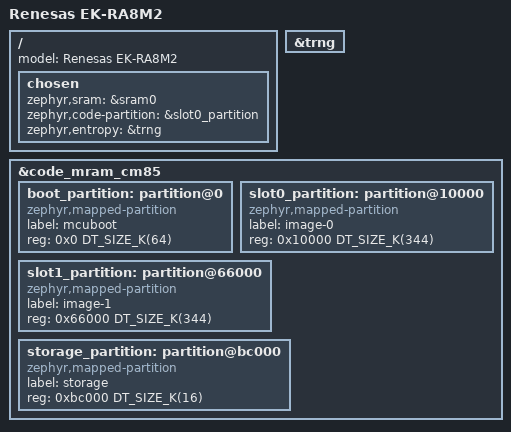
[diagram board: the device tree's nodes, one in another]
/*
 * Copyright (c) 2025-2026 Renesas Electronics Corporation
 *
 * SPDX-License-Identifier: Apache-2.0
 */

/dts-v1/;

#include <renesas/ra/ra8/r7ka8m2jflcac_cm85.dtsi>
#include "ek_ra8m2_r7ka8m2jflcac_cm85_common.dtsi"

/ {
	model = "Renesas EK-RA8M2";

	chosen {
		zephyr,sram = &sram0;
		zephyr,code-partition = &slot0_partition;
		zephyr,entropy = &trng;
	};
};

&trng {
	status = "okay";
};

&code_mram_cm85 {
	boot_partition: partition@0 {
		compatible = "zephyr,mapped-partition";
		label = "mcuboot";
		reg = <0x0 DT_SIZE_K(64)>;
	};

	slot0_partition: partition@10000 {
		compatible = "zephyr,mapped-partition";
		label = "image-0";
		reg = <0x10000 DT_SIZE_K(344)>;
	};

	slot1_partition: partition@66000 {
		compatible = "zephyr,mapped-partition";
		label = "image-1";
		reg = <0x66000 DT_SIZE_K(344)>;
	};

	storage_partition: partition@bc000 {
		compatible = "zephyr,mapped-partition";
		label = "storage";
		reg = <0xbc000 DT_SIZE_K(16)>;
	};
};
